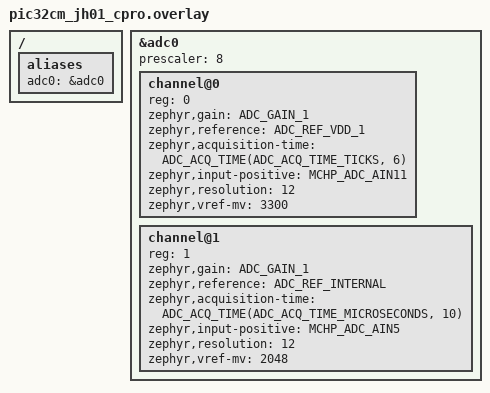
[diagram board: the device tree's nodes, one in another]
/*
 * Copyright (c) 2026 Microchip Technology Inc.
 *
 * SPDX-License-Identifier: Apache-2.0
 */

/ {
	aliases {
		adc0 = &adc0;
	};
};

&adc0 {
	#address-cells = <1>;
	#size-cells = <0>;
	/* ADC clock (TAD) = GCLK1 / prescaler (32 MHz / 8 = 4 MHz) */
	prescaler = <8>;
	status = "okay";

	channel@0 {
		reg = <0>;
		zephyr,gain = "ADC_GAIN_1";
		zephyr,reference = "ADC_REF_VDD_1";
		zephyr,acquisition-time = <ADC_ACQ_TIME(ADC_ACQ_TIME_TICKS, 6)>;
		zephyr,input-positive = <MCHP_ADC_AIN11>; /* EXT1 pin 3 (ADC+) */
		zephyr,resolution = <12>;
		zephyr,vref-mv = <3300>;
	};

	channel@1 {
		reg = <1>;
		zephyr,gain = "ADC_GAIN_1";
		zephyr,reference = "ADC_REF_INTERNAL";
		zephyr,acquisition-time = <ADC_ACQ_TIME(ADC_ACQ_TIME_MICROSECONDS, 10)>;
		zephyr,input-positive = <MCHP_ADC_AIN5>; /* EXT2 pin 3 (ADC+) */
		zephyr,resolution = <12>;
		zephyr,vref-mv = <2048>;
	};
};
